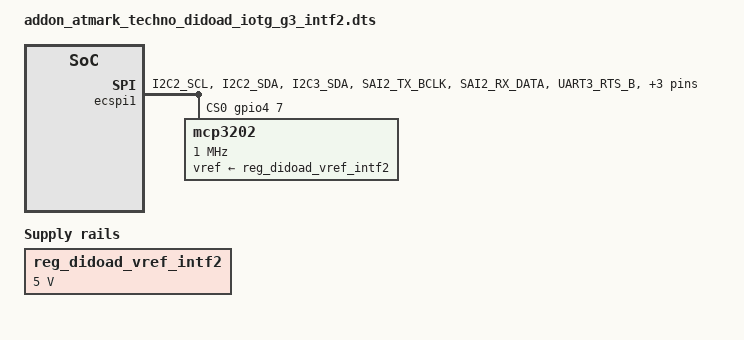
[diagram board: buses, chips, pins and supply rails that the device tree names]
/*
 * Copyright (C) 2017 Atmark Techno, Inc. All Rights Reserved.
 * Author: Daisuke Mizobuchi <mizo@atmark-techno.com>
 *
 * This program is free software; you can redistribute it and/or
 * modify it under the terms of the GNU General Public License
 * version 2 as published by the Free Software Foundation.
 */

#include "../../../../arch/arm/boot/dts/imx7d-pinfunc.h"

/dts-v1/;
/plugin/;
/ {
	fragment@0 {
		target = <&iomuxc>;
		__overlay__ {
			addon-intf2 {
				pinctrl_ecspi1: ecspi1grp {
					fsl,pins = <
						MX7D_PAD_I2C2_SCL__GPIO4_IO10		0x40000000	/* INTF2_24 */
						MX7D_PAD_I2C2_SDA__GPIO4_IO11		0x40000000	/* INTF2_25 */
						MX7D_PAD_I2C3_SDA__GPIO4_IO13		0x00	/* INTF2_43 */
						MX7D_PAD_SAI2_TX_BCLK__GPIO6_IO20	0x70	/* INTF2_47 */
						MX7D_PAD_SAI2_RX_DATA__GPIO6_IO21	0x70	/* INTF2_48 */

						MX7D_PAD_UART3_RTS_B__ECSPI1_SCLK	0x70	/* INTF2_35 */
						MX7D_PAD_UART3_RX_DATA__ECSPI1_MISO	0x70	/* INTF2_36 */
						MX7D_PAD_UART3_TX_DATA__ECSPI1_MOSI	0x70	/* INTF2_37 */
						MX7D_PAD_UART3_CTS_B__GPIO4_IO7		0x70	/* INTF2_50 */
					>;
				};
			};
		};
	};

	fragment@1 {
		target = <&ecspi1>;
		__overlay__ {
			pinctrl-names = "default";
			pinctrl-0 = <&pinctrl_ecspi1>;
			fsl,spi-num-chipselects = <1>;
			cs-gpios = <&gpio4 7 0>;
			status = "okay";

			#address-cells = <1>;
			#size-cells = <0>;
			mcp3202@0 {
				compatible = "mcp3202";
				spi-max-frequency = <1000000>;
				reg = <0>;
				vref-supply = <&reg_didoad_vref_intf2>;
			};
		};
	};

	fragment@2 {
		target = <&regulators>;
		__overlay__ {
			reg_didoad_vref_intf2: reg_didoad_vref_con2 {
				compatible = "regulator-fixed";
				regulator-name = "DIDOAD_VREF";
				regulator-min-microvolt = <5000000>;
				regulator-max-microvolt = <5000000>;
				regulator-always-on;
			};
		};
	};
};
